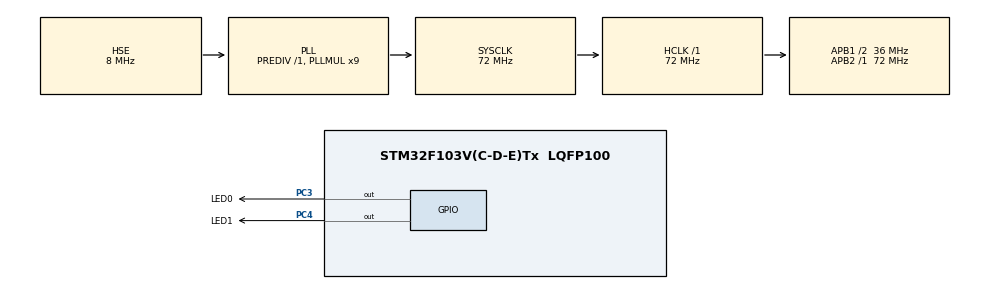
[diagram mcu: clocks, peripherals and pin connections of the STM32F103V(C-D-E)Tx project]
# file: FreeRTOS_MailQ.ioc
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FREERTOS.Tasks01=MailProducer,0,128,MailProducerTask,Default,NULL,Dynamic,NULL,NULL;MailConsumer,0,128,MailConsumerTask,Default,NULL,Dynamic,NULL,NULL
Mcu.Family=STM32F1
Mcu.Name=STM32F103V(C-D-E)Tx
Mcu.Package=LQFP100
NVIC.PriorityGroup=NVIC_PRIORITYGROUP_4
NVIC.TIM4_IRQn=true\:0\:0\:false\:false\:true\:false\:false
NVIC.TimeBase=TIM4_IRQn
NVIC.TimeBaseIP=TIM4
OSC_IN.Mode=HSE-External-Oscillator
OSC_IN.Signal=RCC_OSC_IN
OSC_OUT.Mode=HSE-External-Oscillator
OSC_OUT.Signal=RCC_OSC_OUT
PC3.GPIO_Label=LED0
PC3.Signal=GPIO_Output
PC4.GPIO_Label=LED1
PC4.Signal=GPIO_Output
ProjectManager.HeapSize=0x200
ProjectManager.StackSize=0x400
ProjectManager.TargetToolchain=MDK-ARM V5
RCC.AHBFreq_Value=72000000
RCC.APB1CLKDivider=RCC_HCLK_DIV2
RCC.APB1Freq_Value=36000000
RCC.APB1TimFreq_Value=72000000
RCC.APB2Freq_Value=72000000
RCC.APB2TimFreq_Value=72000000
RCC.HCLKFreq_Value=72000000
RCC.PLLMUL=RCC_PLL_MUL9
RCC.PLLSourceVirtual=RCC_PLLSOURCE_HSE
RCC.SYSCLKFreq_VALUE=72000000
RCC.SYSCLKSource=RCC_SYSCLKSOURCE_PLLCLK
RCC.USBFreq_Value=72000000
VP_FREERTOS_VS_ENABLE.Mode=Enabled
VP_SYS_VS_ND.Mode=No_Debug
VP_SYS_VS_tim4.Mode=TIM4
board=FreeRTOS_MailQ

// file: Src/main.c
/**
  ******************************************************************************
  * @file           : main.c
  * @brief          : Main program body
  ******************************************************************************
  * This notice applies to any and all portions of this file
  * that are not between comment pairs USER CODE BEGIN and
  * USER CODE END. Other portions of this file, whether
  * inserted by the user or by software development tools
  * are owned by their respective copyright owners.
  *
  * Copyright (c) 2018 STMicroelectronics International N.V.
  * All rights reserved.
  *
  * Redistribution and use in source and binary forms, with or without
  * modification, are permitted, provided that the following conditions are met:
  *
  * 1. Redistribution of source code must retain the above copyright notice,
  *    this list of conditions and the following disclaimer.
  * 2. Redistributions in binary form must reproduce the above copyright notice,
  *    this list of conditions and the following disclaimer in the documentation
  *    and/or other materials provided with the distribution.
  * 3. Neither the name of STMicroelectronics nor the names of other
  *    contributors to this software may be used to endorse or promote products
  *    derived from this software without specific written permission.
  * 4. This software, including modifications and/or derivative works of this
  *    software, must execute solely and exclusively on microcontroller or
  *    microprocessor devices manufactured by or for STMicroelectronics.
  * 5. Redistribution and use of this software other than as permitted under
  *    this license is void and will automatically terminate your rights under
  *    this license.
  *
  * THIS SOFTWARE IS PROVIDED BY STMICROELECTRONICS AND CONTRIBUTORS "AS IS"
  * AND ANY EXPRESS, IMPLIED OR STATUTORY WARRANTIES, INCLUDING, BUT NOT
  * LIMITED TO, THE IMPLIED WARRANTIES OF MERCHANTABILITY, FITNESS FOR A
  * PARTICULAR PURPOSE AND NON-INFRINGEMENT OF THIRD PARTY INTELLECTUAL PROPERTY
  * RIGHTS ARE DISCLAIMED TO THE FULLEST EXTENT PERMITTED BY LAW. IN NO EVENT
  * SHALL STMICROELECTRONICS OR CONTRIBUTORS BE LIABLE FOR ANY DIRECT, INDIRECT,
  * INCIDENTAL, SPECIAL, EXEMPLARY, OR CONSEQUENTIAL DAMAGES (INCLUDING, BUT NOT
  * LIMITED TO, PROCUREMENT OF SUBSTITUTE GOODS OR SERVICES; LOSS OF USE, DATA,
  * OR PROFITS; OR BUSINESS INTERRUPTION) HOWEVER CAUSED AND ON ANY THEORY OF
  * LIABILITY, WHETHER IN CONTRACT, STRICT LIABILITY, OR TORT (INCLUDING
  * NEGLIGENCE OR OTHERWISE) ARISING IN ANY WAY OUT OF THE USE OF THIS SOFTWARE,
  * EVEN IF ADVISED OF THE POSSIBILITY OF SUCH DAMAGE.
  *
  ******************************************************************************
  */
#include "main.h"
#include "stm32f1xx_hal.h"
#include "cmsis_os.h"

osThreadId MailProducerHandle;
osThreadId MailConsumerHandle;

/* USER CODE BEGIN PV */
/* Private variables ---------------------------------------------------------*/

/* USER CODE END PV */

void SystemClock_Config(void);
static void MX_GPIO_Init(void);
void MailProducerTask(void const * argument);
void MailConsumerTask(void const * argument);

/* USER CODE BEGIN PFP */
/* Private function prototypes -----------------------------------------------*/

//定义邮箱队列要使用的数据结构
typedef struct
{
	uint32_t var1;
	uint32_t var2;
	uint8_t var3;
} Amail_TypeDef;
//创建一个osMailQId变量，实际就是一个指针

osMailQId mailQ01Handle;
/* USER CODE END PFP */

int main(void)
{

  /* MCU Configuration----------------------------------------------------------*/

  /* Reset of all peripherals, Initializes the Flash interface and the Systick. */
  HAL_Init();

  /* Configure the system clock */
  SystemClock_Config();

  /* Initialize all configured peripherals */
  MX_GPIO_Init();
  /* USER CODE BEGIN 2 */

	//创建邮箱队列，队列深度为15
	osMailQDef(mailQ01, 15, Amail_TypeDef);
	mailQ01Handle = osMailCreate(osMailQ(mailQ01), NULL);

  /* USER CODE END 2 */

  /* Create the thread(s) */
  /* definition and creation of MailProducer */
  osThreadDef(MailProducer, MailProducerTask, osPriorityNormal, 0, 128);
  MailProducerHandle = osThreadCreate(osThread(MailProducer), NULL);

  /* definition and creation of MailConsumer */
  osThreadDef(MailConsumer, MailConsumerTask, osPriorityNormal, 0, 128);
  MailConsumerHandle = osThreadCreate(osThread(MailConsumer), NULL);

  /* Start scheduler */
  osKernelStart();

  /* We should never get here as control is now taken by the scheduler */

  /* Infinite loop */
  while (1)
  {

  }

}

void SystemClock_Config(void)
{

  RCC_OscInitTypeDef RCC_OscInitStruct;
  RCC_ClkInitTypeDef RCC_ClkInitStruct;

    /**Initializes the CPU, AHB and APB busses clocks
    */
  RCC_OscInitStruct.OscillatorType = RCC_OSCILLATORTYPE_HSE;
  RCC_OscInitStruct.HSEState = RCC_HSE_ON;
  RCC_OscInitStruct.HSEPredivValue = RCC_HSE_PREDIV_DIV1;
  RCC_OscInitStruct.HSIState = RCC_HSI_ON;
  RCC_OscInitStruct.PLL.PLLState = RCC_PLL_ON;
  RCC_OscInitStruct.PLL.PLLSource = RCC_PLLSOURCE_HSE;
  RCC_OscInitStruct.PLL.PLLMUL = RCC_PLL_MUL9;
  if (HAL_RCC_OscConfig(&RCC_OscInitStruct) != HAL_OK)
  {
    _Error_Handler(__FILE__, __LINE__);
  }

    /**Initializes the CPU, AHB and APB busses clocks
    */
  RCC_ClkInitStruct.ClockType = RCC_CLOCKTYPE_HCLK|RCC_CLOCKTYPE_SYSCLK
                              |RCC_CLOCKTYPE_PCLK1|RCC_CLOCKTYPE_PCLK2;
  RCC_ClkInitStruct.SYSCLKSource = RCC_SYSCLKSOURCE_PLLCLK;
  RCC_ClkInitStruct.AHBCLKDivider = RCC_SYSCLK_DIV1;
  RCC_ClkInitStruct.APB1CLKDivider = RCC_HCLK_DIV2;
  RCC_ClkInitStruct.APB2CLKDivider = RCC_HCLK_DIV1;

  if (HAL_RCC_ClockConfig(&RCC_ClkInitStruct, FLASH_LATENCY_2) != HAL_OK)
  {
    _Error_Handler(__FILE__, __LINE__);
  }

    /**Configure the Systick interrupt time
    */
  HAL_SYSTICK_Config(HAL_RCC_GetHCLKFreq()/1000);

    /**Configure the Systick
    */
  HAL_SYSTICK_CLKSourceConfig(SYSTICK_CLKSOURCE_HCLK);

  /* SysTick_IRQn interrupt configuration */
  HAL_NVIC_SetPriority(SysTick_IRQn, 15, 0);
}

/** Configure pins as
        * Analog
        * Input
        * Output
        * EVENT_OUT
        * EXTI
*/
static void MX_GPIO_Init(void)
{

  GPIO_InitTypeDef GPIO_InitStruct;

  /* GPIO Ports Clock Enable */
  __HAL_RCC_GPIOC_CLK_ENABLE();

  /*Configure GPIO pin Output Level */
  HAL_GPIO_WritePin(GPIOC, LED0_Pin|LED1_Pin, GPIO_PIN_RESET);

  /*Configure GPIO pins : LED0_Pin LED1_Pin */
  GPIO_InitStruct.Pin = LED0_Pin|LED1_Pin;
  GPIO_InitStruct.Mode = GPIO_MODE_OUTPUT_PP;
  GPIO_InitStruct.Speed = GPIO_SPEED_FREQ_LOW;
  HAL_GPIO_Init(GPIOC, &GPIO_InitStruct);

}

/* MailProducerTask function */
void MailProducerTask(void const * argument)
{

  /* USER CODE BEGIN 5 */
		Amail_TypeDef Mail[3];

		Mail[0].var1 = 0x01; /*设置邮件内容*/
		Mail[0].var2 = 0x02;
		Mail[0].var3 = 0x03;

		Mail[1].var1 = 0x02;
		Mail[1].var2 = 0x03;
		Mail[1].var3 = 0x04;

		Mail[2].var1 = 0x03;
		Mail[2].var2 = 0x04;
		Mail[2].var3 = 0x05;
  /* Infinite loop */
  for(;;)
  {
		osMailPut(mailQ01Handle, &Mail[0]); //发送邮件
    osDelay(1000);
		osMailPut(mailQ01Handle, &Mail[1]); //发送邮件
    osDelay(1000);
		osMailPut(mailQ01Handle, &Mail[2]); //发送邮件
    osDelay(3000);
  }
  /* USER CODE END 5 */
}

/* MailConsumerTask function */
void MailConsumerTask(void const * argument)
{
  /* USER CODE BEGIN MailConsumerTask */
	osEvent event;
	Amail_TypeDef *pMail;
	uint32_t cnt;
  /* Infinite loop */
  for(;;)
  {
		event = osMailGet(mailQ01Handle, osWaitForever); //获取邮件
		if(event.status == osEventMail)
		{
			pMail = event.value.p; //获取邮件指针
			cnt = pMail -> var1; //提取邮件中的数据var2（当然也可以是其它数据）
			while(cnt--) //根据邮箱中传来的数据var2执行递减循环控制LED灯
			{							//0x01就是控制LED闪一次，0x02就是闪两次
										//证明两个进程间进行了非常有效的通信
				HAL_GPIO_WritePin( LED0_GPIO_Port, LED0_Pin, GPIO_PIN_RESET);	//LED0亮
				HAL_GPIO_WritePin( LED1_GPIO_Port, LED1_Pin, GPIO_PIN_RESET);	//LED1亮
				osDelay(100);

				HAL_GPIO_WritePin( LED0_GPIO_Port, LED0_Pin, GPIO_PIN_SET);		//LED0灭
				HAL_GPIO_WritePin( LED1_GPIO_Port, LED1_Pin, GPIO_PIN_SET);		//LED1灭
				osDelay(100);
			}
		}
    osDelay(1);
  }
  /* USER CODE END MailConsumerTask */
}

void HAL_TIM_PeriodElapsedCallback(TIM_HandleTypeDef *htim)
{
  if (htim->Instance == TIM4) {
    HAL_IncTick();
  }
}

void _Error_Handler(char *file, int line)
{
  while(1)
  {
  }
}

/************************ (C) COPYRIGHT STMicroelectronics *****END OF FILE****/
